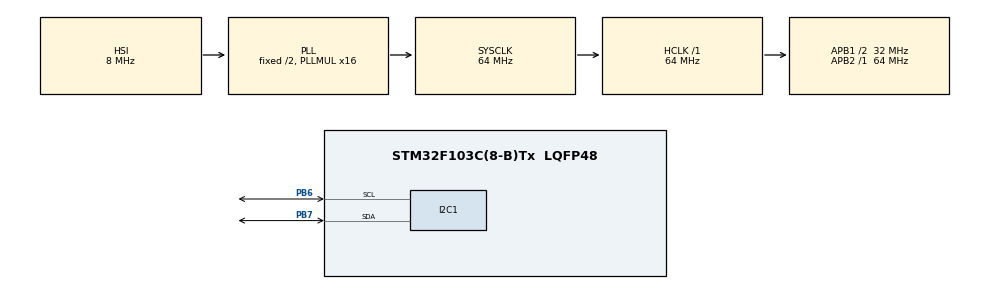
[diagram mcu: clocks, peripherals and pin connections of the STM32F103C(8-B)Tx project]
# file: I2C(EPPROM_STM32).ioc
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Mcu.Family=STM32F1
Mcu.Name=STM32F103C(8-B)Tx
Mcu.Package=LQFP48
NVIC.PriorityGroup=NVIC_PRIORITYGROUP_4
PA13.Mode=Serial_Wire
PA13.Signal=SYS_JTMS-SWDIO
PA14.Mode=Serial_Wire
PA14.Signal=SYS_JTCK-SWCLK
PB6.Mode=I2C
PB6.Signal=I2C1_SCL
PB7.Mode=I2C
PB7.Signal=I2C1_SDA
ProjectManager.HeapSize=0x200
ProjectManager.StackSize=0x400
ProjectManager.TargetToolchain=MDK-ARM V5.32
RCC.AHBFreq_Value=64000000
RCC.APB1CLKDivider=RCC_HCLK_DIV2
RCC.APB1Freq_Value=32000000
RCC.APB1TimFreq_Value=64000000
RCC.APB2Freq_Value=64000000
RCC.APB2TimFreq_Value=64000000
RCC.HCLKFreq_Value=64000000
RCC.PLLMUL=RCC_PLL_MUL16
RCC.SYSCLKFreq_VALUE=64000000
RCC.SYSCLKSource=RCC_SYSCLKSOURCE_PLLCLK
RCC.USBFreq_Value=64000000
board=custom

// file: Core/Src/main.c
/* USER CODE BEGIN Header */
/**
  ******************************************************************************
  * @file           : main.c
  * @brief          : Main program body
  ******************************************************************************
  * @attention
  *
  * <h2><center>&copy; Copyright (c) 2023 STMicroelectronics.
  * All rights reserved.</center></h2>
  *
  * This software component is licensed by ST under BSD 3-Clause license,
  * the "License"; You may not use this file except in compliance with the
  * License. You may obtain a copy of the License at:
  *                        opensource.org/licenses/BSD-3-Clause
  *
  ******************************************************************************
  */
/* USER CODE END Header */
#include "main.h"
#include "stdio.h"
#include "string.h"
/* USER CODE BEGIN Includes */
#define SLAVE_ADDRESS 0xA0
#define MEMORY_ADDRESS 0x1AA
/* USER CODE END Includes */

I2C_HandleTypeDef hi2c1;

void SystemClock_Config(void);
static void MX_GPIO_Init(void);
static void MX_I2C1_Init(void);
HAL_StatusTypeDef Read_From_24lc(I2C_HandleTypeDef *hi2c, uint16_t DevAddress,uint16_t MemoryAddress, uint8_t *pData, uint16_t Size );
HAL_StatusTypeDef  Write_To_24lc(I2C_HandleTypeDef *hi2c, uint16_t DevAddress,uint16_t MemoryAddress, uint8_t *pData, uint16_t Size);

int main(void)
{
  /* USER CODE BEGIN 1 */
const char wmsg[] = "We love STM32!";
char rmsg[20];

  /* USER CODE END 1 */
	// Nhiem vu:Gui chuoi nay vao
  /* MCU Configuration--------------------------------------------------------*/

  /* Reset of all peripherals, Initializes the Flash interface and the Systick. */
  HAL_Init();

  /* Configure the system clock */
  SystemClock_Config();

  /* Initialize all configured peripherals */
  MX_GPIO_Init();
  MX_I2C1_Init();
  /* USER CODE BEGIN 2 */
  Write_To_24lc(&hi2c1,(uint16_t)SLAVE_ADDRESS,(uint16_t)MEMORY_ADDRESS,(uint8_t*)wmsg,strlen(wmsg)+1);
	// tai sao la strlen(wmsg)+1: vi doi vs char[] ham strlen se bo qua "0\n" nen can cong them 1 de so sanh
  Read_From_24lc(&hi2c1,(uint16_t)SLAVE_ADDRESS,(uint16_t)MEMORY_ADDRESS,(uint8_t*)rmsg,strlen(rmsg)+1);
  /* USER CODE END 2 */
  if(strcmp(rmsg,wmsg)==0)
	{
  /* Infinite loop */
  while (1)
  {
  // code every thingk
  }
}
}

void SystemClock_Config(void)
{
  RCC_OscInitTypeDef RCC_OscInitStruct = {0};
  RCC_ClkInitTypeDef RCC_ClkInitStruct = {0};

  /** Initializes the RCC Oscillators according to the specified parameters
  * in the RCC_OscInitTypeDef structure.
  */
  RCC_OscInitStruct.OscillatorType = RCC_OSCILLATORTYPE_HSI;
  RCC_OscInitStruct.HSIState = RCC_HSI_ON;
  RCC_OscInitStruct.HSICalibrationValue = RCC_HSICALIBRATION_DEFAULT;
  RCC_OscInitStruct.PLL.PLLState = RCC_PLL_ON;
  RCC_OscInitStruct.PLL.PLLSource = RCC_PLLSOURCE_HSI_DIV2;
  RCC_OscInitStruct.PLL.PLLMUL = RCC_PLL_MUL16;
  if (HAL_RCC_OscConfig(&RCC_OscInitStruct) != HAL_OK)
  {
    Error_Handler();
  }
  /** Initializes the CPU, AHB and APB buses clocks
  */
  RCC_ClkInitStruct.ClockType = RCC_CLOCKTYPE_HCLK|RCC_CLOCKTYPE_SYSCLK
                              |RCC_CLOCKTYPE_PCLK1|RCC_CLOCKTYPE_PCLK2;
  RCC_ClkInitStruct.SYSCLKSource = RCC_SYSCLKSOURCE_PLLCLK;
  RCC_ClkInitStruct.AHBCLKDivider = RCC_SYSCLK_DIV1;
  RCC_ClkInitStruct.APB1CLKDivider = RCC_HCLK_DIV2;
  RCC_ClkInitStruct.APB2CLKDivider = RCC_HCLK_DIV1;

  if (HAL_RCC_ClockConfig(&RCC_ClkInitStruct, FLASH_LATENCY_2) != HAL_OK)
  {
    Error_Handler();
  }
}

static void MX_I2C1_Init(void)
{

  hi2c1.Instance = I2C1;
  hi2c1.Init.ClockSpeed = 100000;
  hi2c1.Init.DutyCycle = I2C_DUTYCYCLE_2;
  hi2c1.Init.OwnAddress1 = 0;
  hi2c1.Init.AddressingMode = I2C_ADDRESSINGMODE_7BIT;
  hi2c1.Init.DualAddressMode = I2C_DUALADDRESS_DISABLE;
  hi2c1.Init.OwnAddress2 = 0;
  hi2c1.Init.GeneralCallMode = I2C_GENERALCALL_DISABLE;
  hi2c1.Init.NoStretchMode = I2C_NOSTRETCH_DISABLE;
  if (HAL_I2C_Init(&hi2c1) != HAL_OK)
  {
    Error_Handler();
  }

}
//
HAL_StatusTypeDef Read_From_24lc(I2C_HandleTypeDef *hi2c, uint16_t DevAddress, uint16_t MemoryAddress,uint8_t *pData, uint16_t Size)
{
	HAL_StatusTypeDef returnValue;
	uint8_t arr[2];
	// thay dia chi memory 12 bit tuy nhien do moi lan chi gui dc 8 bit nên can phai tach dia chi memory ra truoc khi gui
	// VD:0x1AA thi se duoc gui 2 lan + Lan 1: 0x01(hay 0x1)
	//                                + Lan 2:0xAA
	arr[0]=(uint8_t)((MemoryAddress&0xFF00)>>8); // 0x01AA&0xff00=0x0100  ; 0x0100>>8=0x0001=0x01
	arr[1]=(uint8_t) (MemoryAddress&0xFF); // 0x1AA&0x0ff=0xAA

	// The fist: Sen slave address and memory address
	returnValue=HAL_I2C_Master_Transmit(&hi2c1,DevAddress,arr,2,HAL_MAX_DELAY);
	if(returnValue!=HAL_OK)
	{
			return returnValue;
	}
	// The second :Read data from sensor
	returnValue=HAL_I2C_Master_Receive(&hi2c1,DevAddress,pData,Size,HAL_MAX_DELAY);

	return returnValue;

	}
HAL_StatusTypeDef Write_To_24lc(I2C_HandleTypeDef *hi2c, uint16_t DevAddress, uint16_t MemoryAddress,uint8_t *pData, uint16_t Size)
{
	HAL_StatusTypeDef returnVlue;
	uint8_t *data;
	data=(uint8_t *)malloc(sizeof(uint8_t)*(Size+2)); //them 2 de dung de lua dia chi memory address
	// thay dia chi memory 12 bit tuy nhien do moi lan chi gui dc 8 bit nên can phai tach dia chi memory ra truoc khi gui
	// VD:0x1AA thi se duoc gui 2 lan + Lan 1: 0x01(hay 0x1)
	//                                + Lan 2:0xAA
	data[0]=(uint8_t)((MemoryAddress&0xFF00)>>8); // 0x01AA&0xff00=0x0100  ; 0x0100>>8=0x0001=0x01
	data[1]=(uint8_t) (MemoryAddress&0xFF); // 0x1AA&0x0ff=0xAA
	memcpy(data+2,pData,Size+2);

	returnVlue=HAL_I2C_Master_Transmit(&hi2c1,DevAddress,data,Size+2,HAL_MAX_DELAY);
	return returnVlue;

	}

static void MX_GPIO_Init(void)
{

  /* GPIO Ports Clock Enable */
  __HAL_RCC_GPIOA_CLK_ENABLE();
  __HAL_RCC_GPIOB_CLK_ENABLE();

}

void Error_Handler(void)
{
  __disable_irq();
  while (1)
  {
  }
}

/************************ (C) COPYRIGHT STMicroelectronics *****END OF FILE****/
